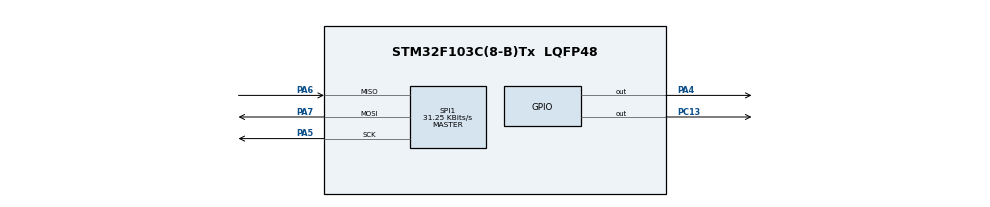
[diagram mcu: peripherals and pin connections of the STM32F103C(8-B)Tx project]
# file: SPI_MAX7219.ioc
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Mcu.Family=STM32F1
Mcu.Name=STM32F103C(8-B)Tx
Mcu.Package=LQFP48
NVIC.PriorityGroup=NVIC_PRIORITYGROUP_4
PA13.Mode=Trace_Asynchronous_SW
PA13.Signal=SYS_JTMS-SWDIO
PA14.Mode=Trace_Asynchronous_SW
PA14.Signal=SYS_JTCK-SWCLK
PA4.Signal=GPIO_Output
PA5.Mode=Full_Duplex_Master
PA5.Signal=SPI1_SCK
PA6.Mode=Full_Duplex_Master
PA6.Signal=SPI1_MISO
PA7.Mode=Full_Duplex_Master
PA7.Signal=SPI1_MOSI
PB3.Mode=Trace_Asynchronous_SW
PB3.Signal=SYS_JTDO-TRACESWO
PC13-TAMPER-RTC.Signal=GPIO_Output
ProjectManager.HeapSize=0x200
ProjectManager.StackSize=0x400
ProjectManager.TargetToolchain=Makefile
RCC.APB1Freq_Value=8000000
RCC.APB2Freq_Value=8000000
SPI1.BaudRatePrescaler=SPI_BAUDRATEPRESCALER_256
SPI1.CLKPhase=SPI_PHASE_2EDGE
SPI1.CLKPolarity=SPI_POLARITY_HIGH
SPI1.CalculateBaudRate=31.25 KBits/s
SPI1.Direction=SPI_DIRECTION_2LINES
SPI1.Mode=SPI_MODE_MASTER
SPI1.VirtualType=VM_MASTER
board=custom

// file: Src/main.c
/* USER CODE BEGIN Header */
/**
  ******************************************************************************
  * @file           : main.c
  * @brief          : Main program body
  ******************************************************************************
  * @attention
  *
  * <h2><center>&copy; Copyright (c) 2020 STMicroelectronics.
  * All rights reserved.</center></h2>
  *
  * This software component is licensed by ST under BSD 3-Clause license,
  * the "License"; You may not use this file except in compliance with the
  * License. You may obtain a copy of the License at:
  *                        opensource.org/licenses/BSD-3-Clause
  *
  ******************************************************************************
  */
/* USER CODE END Header */
#include "main.h"
#include "spi.h"
#include "gpio.h"

/* USER CODE BEGIN Includes */
#include "MAX7219.h"
/* USER CODE END Includes */

void SystemClock_Config(void);

int main(void)
{

  /* MCU Configuration--------------------------------------------------------*/

  /* Reset of all peripherals, Initializes the Flash interface and the Systick. */

  LL_APB2_GRP1_EnableClock(LL_APB2_GRP1_PERIPH_AFIO);
  LL_APB1_GRP1_EnableClock(LL_APB1_GRP1_PERIPH_PWR);

  NVIC_SetPriorityGrouping(NVIC_PRIORITYGROUP_4);

  /* System interrupt init*/

  /** NOJTAG: JTAG-DP Disabled and SW-DP Enabled
  */
  LL_GPIO_AF_Remap_SWJ_NOJTAG();

  /* Configure the system clock */
  SystemClock_Config();

  /* Initialize all configured peripherals */
  MX_GPIO_Init();
  MX_SPI1_Init();
  /* USER CODE BEGIN 2 */
  Configure_SPI();
  Activate_SPI();
  Max7219_Init();
  /* USER CODE END 2 */

  /* Infinite loop */
  while (1)
  {

    /* USER CODE BEGIN 3 */
    for (uint16_t i = 0; i < 8; i++)
    {
      Write_Max7219(0x01 + i, 0xFF << i);
    }

    LL_GPIO_TogglePin(GPIOC, LL_GPIO_PIN_13);
    LL_mDelay(1000);

    for (uint16_t i = 0; i < 8; i++)
    {
      Write_Max7219(0x01 + i, 0xFF >> i);
    }

    LL_GPIO_TogglePin(GPIOC, LL_GPIO_PIN_13);
    LL_mDelay(1000);
  }
  /* USER CODE END 3 */
}

void SystemClock_Config(void)
{
  LL_FLASH_SetLatency(LL_FLASH_LATENCY_0);
  while(LL_FLASH_GetLatency()!= LL_FLASH_LATENCY_0)
  {
  }
  LL_RCC_HSI_SetCalibTrimming(16);
  LL_RCC_HSI_Enable();

   /* Wait till HSI is ready */
  while(LL_RCC_HSI_IsReady() != 1)
  {

  }
  LL_RCC_SetAHBPrescaler(LL_RCC_SYSCLK_DIV_1);
  LL_RCC_SetAPB1Prescaler(LL_RCC_APB1_DIV_1);
  LL_RCC_SetAPB2Prescaler(LL_RCC_APB2_DIV_1);
  LL_RCC_SetSysClkSource(LL_RCC_SYS_CLKSOURCE_HSI);

   /* Wait till System clock is ready */
  while(LL_RCC_GetSysClkSource() != LL_RCC_SYS_CLKSOURCE_STATUS_HSI)
  {

  }
  LL_Init1msTick(8000000);
  LL_SetSystemCoreClock(8000000);
}

void Error_Handler(void)
{
}

/************************ (C) COPYRIGHT STMicroelectronics *****END OF FILE****/
